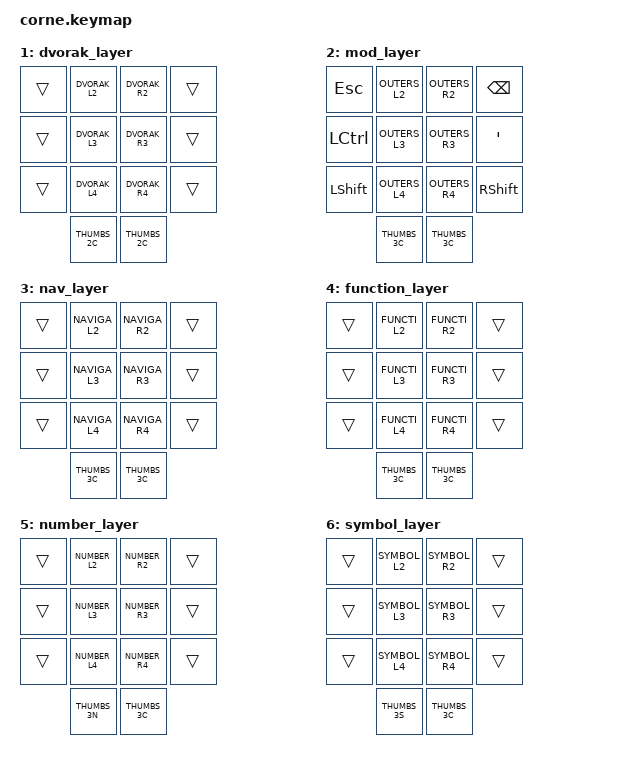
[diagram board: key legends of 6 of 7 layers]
/*
 * Copyright (c) 2020 The ZMK Contributors
 *
 * SPDX-License-Identifier: MIT
 */

#include <behaviors.dtsi>
#include "include/definitions.c"

/ {
        #include "behaviors/combos.dtsi"
        keymap {
                compatible = "zmk,keymap";
                qwerty_layer {
                        bindings = <
                                &trans    QWERTY_L2  QWERTY_R2 &trans
                                &trans    QWERTY_L3  QWERTY_R3 &trans
                                &trans    QWERTY_L4  QWERTY_R4 &trans
                                &trans    THUMBS_2L  THUMBS_2R &trans
                        >;
                };
                dvorak_layer {
                        bindings = <
                                &trans    DVORAK_L2  DVORAK_R2 &trans
                                &trans    DVORAK_L3  DVORAK_R3 &trans
                                &trans    DVORAK_L4  DVORAK_R4 &trans
                                          THUMBS_2C  THUMBS_2C
                        >;
                };
                mod_layer {
                        bindings = <
                                &kp ESC   OUTERS_L2  OUTERS_R2 &kp BSPC
                                &kp LCTRL OUTERS_L3  OUTERS_R3 &kp SQT
                                &kp LSHFT OUTERS_L4  OUTERS_R4 &kp RSHFT
                                          THUMBS_3C  THUMBS_3C
                        >;
                };
                nav_layer {
                        bindings = <
                                &trans    NAVIGA_L2  NAVIGA_R2 &trans
                                &trans    NAVIGA_L3  NAVIGA_R3 &trans
                                &trans    NAVIGA_L4  NAVIGA_R4 &trans
                                          THUMBS_3C  THUMBS_3C
                        >;
                };
                function_layer {
                        bindings = <
                                &trans    FUNCTI_L2  FUNCTI_R2 &trans
                                &trans    FUNCTI_L3  FUNCTI_R3 &trans
                                &trans    FUNCTI_L4  FUNCTI_R4 &trans
                                          THUMBS_3C  THUMBS_3C
                        >;
                };

                number_layer {
                        bindings = <
                                &trans    NUMBER_L2  NUMBER_R2 &trans
                                &trans    NUMBER_L3  NUMBER_R3 &trans
                                &trans    NUMBER_L4  NUMBER_R4 &trans
                                          THUMBS_3N  THUMBS_3C
                        >;
                };
                symbol_layer {
                        bindings = <
                                &trans    SYMBOL_L2  SYMBOL_R2 &trans
                                &trans    SYMBOL_L3  SYMBOL_R3 &trans
                                &trans    SYMBOL_L4  SYMBOL_R4 &trans
                                          THUMBS_3S  THUMBS_3C
                        >;
                };
        };
};

// vim: filetype=dts
